VERSION "cockpit_mini 1.0"

BU_: DCU HMI VCU

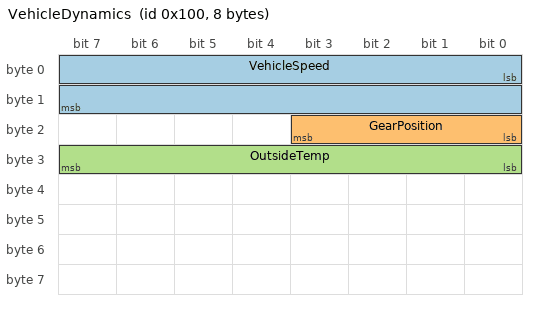
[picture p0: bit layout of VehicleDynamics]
BO_ 256 VehicleDynamics: 8 DCU
 SG_ VehicleSpeed : 0|16@1+ (0.1,0) [0|250] "km/h" HMI,VCU
 SG_ GearPosition : 16|4@1+ (1,0) [0|7] "" HMI,VCU
 SG_ OutsideTemp : 24|8@1+ (1,-40) [-40|85] "degC" HMI

BO_ 768 BluetoothStatus: 8 DCU
 SG_ BtState : 0|4@1+ (1,0) [0|7] "" HMI
 SG_ PairedCount : 4|8@1+ (1,0) [0|255] "" HMI

VAL_ 256 GearPosition 0 "P" 1 "R" 2 "N" 3 "D" ;
VAL_ 768 BtState 0 "off" 1 "pairing" 2 "connected" 3 "disconnected" ;
